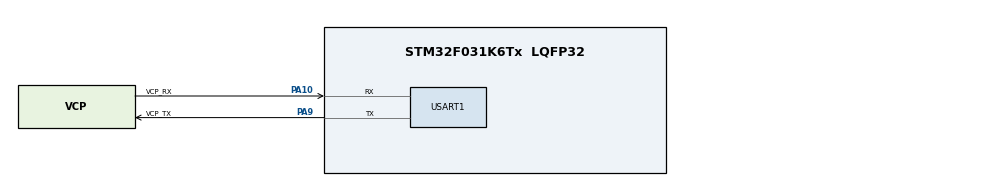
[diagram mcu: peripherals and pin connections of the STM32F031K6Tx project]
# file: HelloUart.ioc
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Mcu.Family=STM32F0
Mcu.Name=STM32F031K6Tx
Mcu.Package=LQFP32
PA10.GPIO_Label=VCP_RX
PA10.Mode=Asynchronous
PA10.Signal=USART1_RX
PA13.GPIO_Label=SWDIO
PA13.Signal=SYS_SWDIO
PA14.GPIO_Label=SWCLK
PA14.Signal=SYS_SWCLK
PA9.GPIO_Label=VCP_TX
PA9.Mode=Asynchronous
PA9.Signal=USART1_TX
PF0-OSC_IN.Signal=RCC_OSC_IN
ProjectManager.HeapSize=0x200
ProjectManager.StackSize=0x400
ProjectManager.TargetToolchain=SW4STM32
USART1.VirtualMode-Asynchronous=VM_ASYNC
board=NUCLEO-F031K6

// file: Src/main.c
/**
  ******************************************************************************
  * File Name          : main.c
  * Description        : Main program body
  ******************************************************************************
  *
  * COPYRIGHT(c) 2017 STMicroelectronics
  *
  * Redistribution and use in source and binary forms, with or without modification,
  * are permitted provided that the following conditions are met:
  *   1. Redistributions of source code must retain the above copyright notice,
  *      this list of conditions and the following disclaimer.
  *   2. Redistributions in binary form must reproduce the above copyright notice,
  *      this list of conditions and the following disclaimer in the documentation
  *      and/or other materials provided with the distribution.
  *   3. Neither the name of STMicroelectronics nor the names of its contributors
  *      may be used to endorse or promote products derived from this software
  *      without specific prior written permission.
  *
  * THIS SOFTWARE IS PROVIDED BY THE COPYRIGHT HOLDERS AND CONTRIBUTORS "AS IS"
  * AND ANY EXPRESS OR IMPLIED WARRANTIES, INCLUDING, BUT NOT LIMITED TO, THE
  * IMPLIED WARRANTIES OF MERCHANTABILITY AND FITNESS FOR A PARTICULAR PURPOSE ARE
  * DISCLAIMED. IN NO EVENT SHALL THE COPYRIGHT HOLDER OR CONTRIBUTORS BE LIABLE
  * FOR ANY DIRECT, INDIRECT, INCIDENTAL, SPECIAL, EXEMPLARY, OR CONSEQUENTIAL
  * DAMAGES (INCLUDING, BUT NOT LIMITED TO, PROCUREMENT OF SUBSTITUTE GOODS OR
  * SERVICES; LOSS OF USE, DATA, OR PROFITS; OR BUSINESS INTERRUPTION) HOWEVER
  * CAUSED AND ON ANY THEORY OF LIABILITY, WHETHER IN CONTRACT, STRICT LIABILITY,
  * OR TORT (INCLUDING NEGLIGENCE OR OTHERWISE) ARISING IN ANY WAY OUT OF THE USE
  * OF THIS SOFTWARE, EVEN IF ADVISED OF THE POSSIBILITY OF SUCH DAMAGE.
  *
  ******************************************************************************
  */
#include "main.h"
#include "stm32f0xx_hal.h"
#include "usart.h"
#include "gpio.h"

/* USER CODE BEGIN PV */
/* Private variables ---------------------------------------------------------*/
char ctosend[] = {'f', 'u', 'c', 'k', ' '};
uint8_t i, cbufor;
/* USER CODE END PV */

void SystemClock_Config(void);
void Error_Handler(void);

/* USER CODE BEGIN PFP */
/* Private function prototypes -----------------------------------------------*/

/* USER CODE END PFP */

int main(void)
{

  /* MCU Configuration----------------------------------------------------------*/

  /* Reset of all peripherals, Initializes the Flash interface and the Systick. */
  HAL_Init();

  /* Configure the system clock */
  SystemClock_Config();

  /* Initialize all configured peripherals */
  MX_GPIO_Init();
  MX_USART1_UART_Init();

  /* USER CODE BEGIN 2 */
  for(i=0;i<sizeof(ctosend);i++){
	  while(!(USART1->ISR & USART_ISR_TC));//if tx ready to send
	  USART1->TDR = ctosend[i];//send data
  }
  USART1->ICR |= USART_ICR_TCCF; // Clear transfer complete flag

//  HAL_UART_Transmit(&huart1, ctosend, sizeof(ctosend), 1000);
  /* USER CODE END 2 */

  /* Infinite loop */
  /* USER CODE BEGIN WHILE */
  while (1)
  {
	  if(USART1->ISR & USART_ISR_RXNE){//if sometching comed
		  cbufor = (uint8_t)USART1->RDR; //read, clear flag
	  } else if(cbufor == '0'){
		  for(i=0;i<sizeof(ctosend);i++){
			  while(!(USART1->ISR & USART_ISR_TC));//if tx ready to send
			  USART1->TDR = ctosend[i];//send data
		  }
		  USART1->ICR |= USART_ICR_TCCF; // Clear transfer complete flag
	  }
  /* USER CODE END WHILE */

  }

}

/** System Clock Configuration
*/
void SystemClock_Config(void)
{

  RCC_OscInitTypeDef RCC_OscInitStruct;
  RCC_ClkInitTypeDef RCC_ClkInitStruct;
  RCC_PeriphCLKInitTypeDef PeriphClkInit;

    /**Initializes the CPU, AHB and APB busses clocks
    */
  RCC_OscInitStruct.OscillatorType = RCC_OSCILLATORTYPE_HSI;
  RCC_OscInitStruct.HSIState = RCC_HSI_ON;
  RCC_OscInitStruct.HSICalibrationValue = 16;
  RCC_OscInitStruct.PLL.PLLState = RCC_PLL_NONE;
  if (HAL_RCC_OscConfig(&RCC_OscInitStruct) != HAL_OK)
  {
    Error_Handler();
  }

    /**Initializes the CPU, AHB and APB busses clocks
    */
  RCC_ClkInitStruct.ClockType = RCC_CLOCKTYPE_HCLK|RCC_CLOCKTYPE_SYSCLK
                              |RCC_CLOCKTYPE_PCLK1;
  RCC_ClkInitStruct.SYSCLKSource = RCC_SYSCLKSOURCE_HSI;
  RCC_ClkInitStruct.AHBCLKDivider = RCC_SYSCLK_DIV1;
  RCC_ClkInitStruct.APB1CLKDivider = RCC_HCLK_DIV1;

  if (HAL_RCC_ClockConfig(&RCC_ClkInitStruct, FLASH_LATENCY_0) != HAL_OK)
  {
    Error_Handler();
  }

  PeriphClkInit.PeriphClockSelection = RCC_PERIPHCLK_USART1;
  PeriphClkInit.Usart1ClockSelection = RCC_USART1CLKSOURCE_PCLK1;
  if (HAL_RCCEx_PeriphCLKConfig(&PeriphClkInit) != HAL_OK)
  {
    Error_Handler();
  }

    /**Configure the Systick interrupt time
    */
  HAL_SYSTICK_Config(HAL_RCC_GetHCLKFreq()/1000);

    /**Configure the Systick
    */
  HAL_SYSTICK_CLKSourceConfig(SYSTICK_CLKSOURCE_HCLK);

  /* SysTick_IRQn interrupt configuration */
  HAL_NVIC_SetPriority(SysTick_IRQn, 0, 0);
}

void Error_Handler(void)
{
  while(1)
  {
  }
}

/************************ (C) COPYRIGHT STMicroelectronics *****END OF FILE****/
